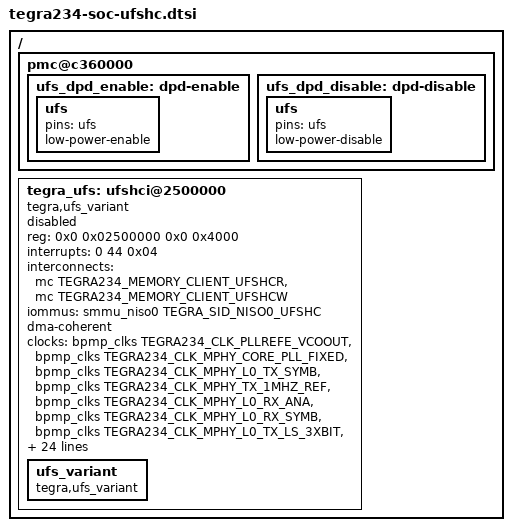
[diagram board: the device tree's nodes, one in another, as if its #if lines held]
/*
 * Copyright (c) 2017-2021, NVIDIA CORPORATION.  All rights reserved.
 *
 * This program is free software; you can redistribute it and/or modify it
 * under the terms and conditions of the GNU General Public License,
 * version 2, as published by the Free Software Foundation.
 *
 * This program is distributed in the hope it will be useful, but WITHOUT
 * ANY WARRANTY; without even the implied warranty of MERCHANTABILITY or
 * FITNESS FOR A PARTICULAR PURPOSE.  See the GNU General Public License for
 * more details.
 *
 * You should have received a copy of the GNU General Public License
 * along with this program.  If not, see <http://www.gnu.org/licenses/>.
 */

/*
 * tegra234-soc-ufshc.dtsi: Tegra234 soc dtsi file for UFS host controller
 */

/ {

	pmc@c360000 {
		ufs_dpd_enable: dpd-enable {
			ufs {
				pins = "ufs";
				low-power-enable;
			};
		};
		ufs_dpd_disable: dpd-disable {
			ufs {
				pins = "ufs";
				low-power-disable;
			};
		};
	};

	tegra_ufs: ufshci@2500000 {
		compatible = "tegra,ufs_variant";
		reg = <0x0 0x02500000 0x0 0x4000>;
		interrupts = < 0 44 0x04 >;
#if TEGRA_IOMMU_DT_VERSION >= DT_VERSION_2
		interconnects = <&mc TEGRA234_MEMORY_CLIENT_UFSHCR>,
			        <&mc TEGRA234_MEMORY_CLIENT_UFSHCW>;
		interconnect-names = "dma-mem", "dma-mem";
#endif

#if TEGRA_IOMMU_DT_VERSION >= DT_VERSION_2
		iommus = <&smmu_niso0 TEGRA_SID_NISO0_UFSHC>;
#else
		iommus = <&smmu TEGRA_SID_UFSHC>;
#endif
		dma-coherent;
		clocks = <&bpmp_clks TEGRA234_CLK_PLLREFE_VCOOUT>,
				<&bpmp_clks TEGRA234_CLK_MPHY_CORE_PLL_FIXED>,
				<&bpmp_clks TEGRA234_CLK_MPHY_L0_TX_SYMB>,
				<&bpmp_clks TEGRA234_CLK_MPHY_TX_1MHZ_REF> ,
				<&bpmp_clks TEGRA234_CLK_MPHY_L0_RX_ANA>,
				<&bpmp_clks TEGRA234_CLK_MPHY_L0_RX_SYMB>,
				<&bpmp_clks TEGRA234_CLK_MPHY_L0_TX_LS_3XBIT>,
				<&bpmp_clks TEGRA234_CLK_MPHY_L0_RX_LS_BIT>,
				<&bpmp_clks TEGRA234_CLK_MPHY_L1_RX_ANA>,
				<&bpmp_clks TEGRA234_CLK_UFSHC>,
				<&bpmp_clks TEGRA234_CLK_UFSDEV_REF>,
				<&bpmp_clks TEGRA234_CLK_PLLP_OUT0>,
				<&bpmp_clks TEGRA234_CLK_CLK_M>,
				<&bpmp_clks TEGRA234_CLK_MPHY_FORCE_LS_MODE>,
				<&bpmp_clks TEGRA234_CLK_UPHY_PLL3>;
		clock-names = "pllrefe_vcoout", "mphy_core_pll_fixed", "mphy_l0_tx_symb",
				"mphy_tx_1mhz_ref", "mphy_l0_rx_ana",
				"mphy_l0_rx_symb", "mphy_l0_tx_ls_3xbit",
				"mphy_l0_rx_ls_bit", "mphy_l1_rx_ana",
				"ufshc", "ufsdev_ref", "pll_p", "clk_m",
				"mphy_force_ls_mode", "uphy_pll3";
		resets = <&bpmp_resets TEGRA194_RESET_MPHY_L0_RX>,
				<&bpmp_resets TEGRA194_RESET_MPHY_L0_TX>,
				<&bpmp_resets TEGRA194_RESET_MPHY_L1_RX>,
				<&bpmp_resets TEGRA194_RESET_MPHY_L1_TX>,
				<&bpmp_resets TEGRA194_RESET_MPHY_CLK_CTL>,
				<&bpmp_resets TEGRA194_RESET_UFSHC>,
				<&bpmp_resets TEGRA194_RESET_UFSHC_AXI_M>,
				<&bpmp_resets TEGRA194_RESET_UFSHC_LP_SEQ>;
		reset-names = "mphy-l0-rx-rst", "mphy-l0-tx-rst", "mphy-l1-rx-rst",
				"mphy-l1-tx-rst", "mphy-clk-ctl-rst", "ufs-rst",
				"ufs-axi-m-rst", "ufshc-lp-rst";
		nvidia,enable-x2-config;
		nvidia,mask-fast-auto-mode;
		nvidia,max-hs-gear = <0>;
		nvidia,max-pwm-gear = <0>;
		vcc-max-microamp = <0>;
		vccq-max-microamp = <0>;
		vccq2-max-microamp = <0>;
		nvidia,configure-uphy-pll3;
		status = "disabled";

		ufs_variant {
			compatible = "tegra,ufs_variant";
		};
	};
};

